# wl_phy_tx_cfg_secure register map
Vendor: Texas Instruments
Registers are 32-bit, access per field, reset 0x0 unless marked. A register's access mark holds for its fields unless they carry their own. Offsets are as the file gives them; [hi:lo] are bit positions; lines under a group give offsets from that group; {n}, {i} and the like mark numbered series.

## wl_phy_tx_cfg_secure
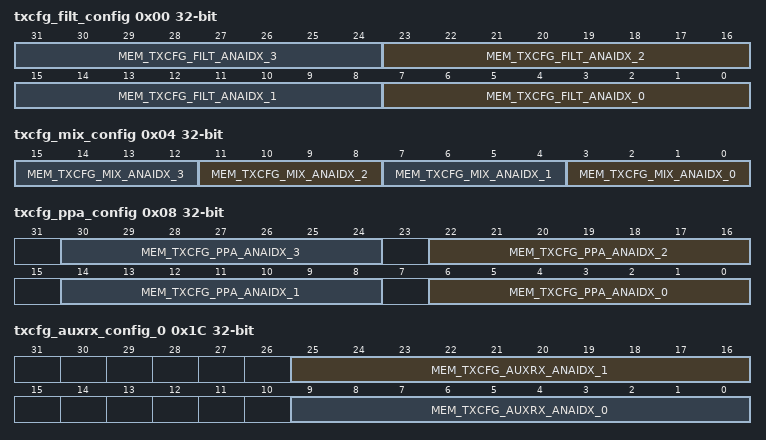
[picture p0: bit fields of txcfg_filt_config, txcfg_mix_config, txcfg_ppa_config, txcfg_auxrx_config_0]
0x00 txcfg_filt_config rw
  [8n+7:8n] MEM_TXCFG_FILT_ANAIDX_{n} (n=0..3) — Configures the specific analogue indexs (x4) Tx filter configuration.
0x04 txcfg_mix_config
  [4n+3:4n] MEM_TXCFG_MIX_ANAIDX_{n} rw (n=0..3) — Configures the specific analogue indexs (x4) Mixer configuration.
0x08 txcfg_ppa_config
  [8n+6:8n] MEM_TXCFG_PPA_ANAIDX_{n} rw (n=0..3) — Configures the specific analogue indexs(x4)PPA configuration.
{0xC+4i} txcfg_pa_config_{i} (i=0..3)
  [16:0] MEM_TXCFG_PA_ANAIDX_{i} rw — Configures the specific analogue indexs(x4)PA configuration.
0x1C txcfg_auxrx_config_0
  [25:16] MEM_TXCFG_AUXRX_ANAIDX_1 rw — Configures the specific analogue indexs(x4)Aux Rx configuration
  [9:0] MEM_TXCFG_AUXRX_ANAIDX_0 rw — Configures the specific analogue indexs(x4)Aux Rx configuration
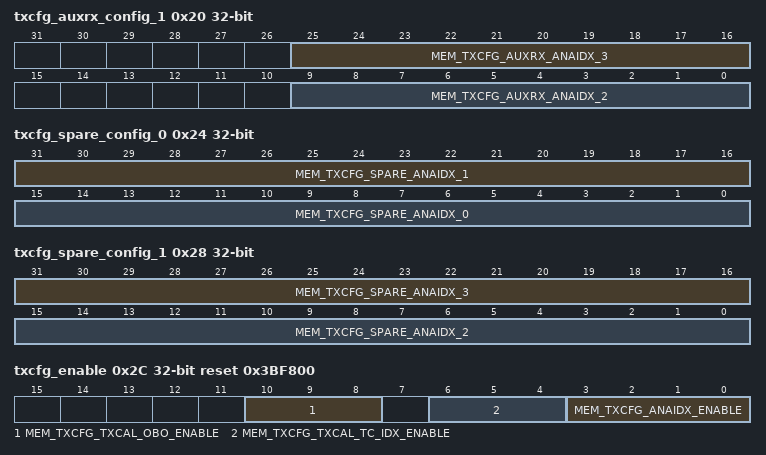
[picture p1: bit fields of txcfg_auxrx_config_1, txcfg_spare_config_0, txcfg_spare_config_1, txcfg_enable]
0x20 txcfg_auxrx_config_1
  [25:16] MEM_TXCFG_AUXRX_ANAIDX_3 rw — Configures the specific analogue indexs(x4)Aux Rx configuration
  [9:0] MEM_TXCFG_AUXRX_ANAIDX_2 rw — Configures the specific analogue indexs(x4)Aux Rx configuration
0x24 txcfg_spare_config_0 rw
  [31:16] MEM_TXCFG_SPARE_ANAIDX_1 — Spare configurations bits per analogue index(x4)
  [15:0] MEM_TXCFG_SPARE_ANAIDX_0 — Spare configurations bits per analogue index(x4)
0x28 txcfg_spare_config_1 rw
  [31:16] MEM_TXCFG_SPARE_ANAIDX_3 — Spare configurations bits per analogue index(x4)
  [15:0] MEM_TXCFG_SPARE_ANAIDX_2 — Spare configurations bits per analogue index(x4)
0x2C txcfg_enable reset 0x3BF800 (reset mask 0xFFFFF800)
  [10:8] MEM_TXCFG_TXCAL_OBO_ENABLE rw — Sets the enable regarding Tx Calibrators request to change the OBO:;MSB allows IQMM only OBO.;The next MSB allows RFNL only OBO.;LSB allows RFNL+IQMM OBO.
  [6:4] MEM_TXCFG_TXCAL_TC_IDX_ENABLE rw — Sets the enables regarding Tx Calibrators request to change the TC:;MSB allows IQMM only TC.;The next MSB allows RFNLonly TC.;LSB allows RFNL+IQMMTC.
  [3:0] MEM_TXCFG_ANAIDX_ENABLE rw — Sets the analogue index enables.MSB controls the high est powerlevel(0).LSBcontrolsthelowest(3).
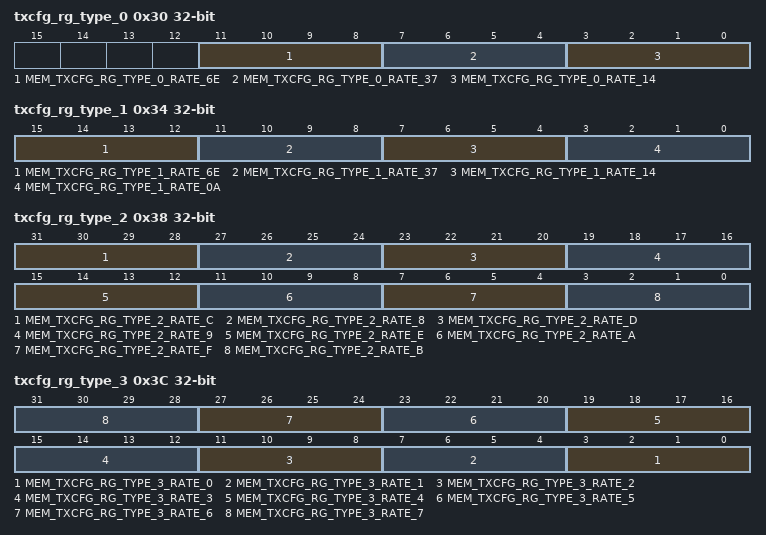
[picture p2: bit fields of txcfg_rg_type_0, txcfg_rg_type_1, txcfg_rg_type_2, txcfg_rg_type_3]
0x30 txcfg_rg_type_0
  [11:8] MEM_TXCFG_RG_TYPE_0_RATE_6E rw — Determines the transmissions rate group from a combination of the signals format and rate. See table 15-1 : Main algorithm ;Full Rate Group Logic Table for more details.
  [7:4] MEM_TXCFG_RG_TYPE_0_RATE_37 rw — Determines the transmissions rate group from a combination of the signals format and rate. See table 15-1 : Main algorithm ;Full Rate Group Logic Table for more details.
  [3:0] MEM_TXCFG_RG_TYPE_0_RATE_14 rw — Determines the transmissions rate group from a combination of the signals format and rate. See table 15-1 : Main algorithm ;Full Rate Group Logic Table for more details.
0x34 txcfg_rg_type_1
  [15:12] MEM_TXCFG_RG_TYPE_1_RATE_6E rw — Determines the transmissions rate group from a combination of the signals format and rate. See table 15-1 : Main algorithm ;Full Rate Group Logic Table for more details.
  [11:8] MEM_TXCFG_RG_TYPE_1_RATE_37 rw — Determines the transmissions rate group from a combination of the signals format and rate. See table 15-1 : Main algorithm ;Full Rate Group Logic Table for more details.
  [7:4] MEM_TXCFG_RG_TYPE_1_RATE_14 rw — Determines the transmissions rate group from a combination of the signals format and rate. See table 15-1 : Main algorithm ;Full Rate Group Logic Table for more details.
  [3:0] MEM_TXCFG_RG_TYPE_1_RATE_0A rw — Determines the transmissions rate group from a combination of the signals format and rate. See table 15-1 : Main algorithm ;Full Rate Group Logic Table for more details.
0x38 txcfg_rg_type_2 rw reset not defined
  [31:28] MEM_TXCFG_RG_TYPE_2_RATE_C — Determines the transmissions rate group from a combination of the signals format and rate. See table 15-1 : Main algorithm ;Full Rate Group Logic Table for more details.
  [27:24] MEM_TXCFG_RG_TYPE_2_RATE_8 — Determines the transmissions rate group from a combination of the signals format and rate. See table 15-1 : Main algorithm ;Full Rate Group Logic Table for more details.
  [23:20] MEM_TXCFG_RG_TYPE_2_RATE_D — Determines the transmissions rate group from a combination of the signals format and rate. See table 15-1 : Main algorithm ;Full Rate Group Logic Table for more details.
  [19:16] MEM_TXCFG_RG_TYPE_2_RATE_9 — Determines the transmissions rate group from a combination of the signals format and rate. See table 15-1 : Main algorithm ;Full Rate Group Logic Table for more details.
  [15:12] MEM_TXCFG_RG_TYPE_2_RATE_E — Determines the transmissions rate group from a combination of the signals format and rate. See table 15-1 : Main algorithm ;Full Rate Group Logic Table for more details.
  [11:8] MEM_TXCFG_RG_TYPE_2_RATE_A — Determines the transmissions rate group from a combination of the signals format and rate. See table 15-1 : Main algorithm ;Full Rate Group Logic Table for more details.
  [7:4] MEM_TXCFG_RG_TYPE_2_RATE_F — Determines the transmissions rate group from a combination of the signals format and rate. See table 15-1 : Main algorithm ;Full Rate Group Logic Table for more details.
  [3:0] MEM_TXCFG_RG_TYPE_2_RATE_B — Determines the transmissions rate group from a combination of the signals format and rate. See table 15-1 : Main algorithm ;Full Rate Group Logic Table for more details.
0x3C txcfg_rg_type_3 rw reset not defined
  [4n+3:4n] MEM_TXCFG_RG_TYPE_3_RATE_{n} (n=0..7) — Determines the transmissions rate group from a combination of the signals format and rate. See table 15-1 : Main algorithm ;Full Rate Group Logic Table for more details.
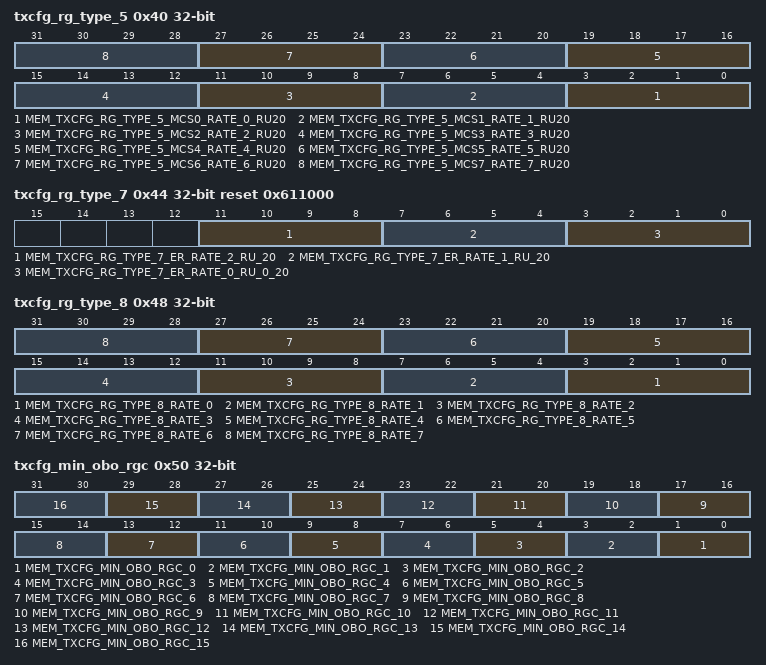
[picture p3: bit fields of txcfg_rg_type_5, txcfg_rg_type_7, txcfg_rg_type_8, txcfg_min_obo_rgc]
0x40 txcfg_rg_type_5 rw reset not defined
  [4n+3:4n] MEM_TXCFG_RG_TYPE_5_MCS{n}_RATE_{n}_RU20 (n=0..7) — Determines the transmissions rate group from a combination of the signals format and rate. See table 15-1 : Main algorithm ;Full Rate Group Logic Table for more details.
0x44 txcfg_rg_type_7 reset 0x611000 (reset mask 0xFFFFF000)
  [11:8] MEM_TXCFG_RG_TYPE_7_ER_RATE_2_RU_20 rw — Determines the transmissions rate group from a combination of the signals format and rate. See table 15-1 : Main algorithm ;Full Rate Group Logic Table for more details.
  [7:4] MEM_TXCFG_RG_TYPE_7_ER_RATE_1_RU_20 rw — Determines the transmissions rate group from a combination of the signals format and rate. See table 15-1 : Main algorithm ;Full Rate Group Logic Table for more details.
  [3:0] MEM_TXCFG_RG_TYPE_7_ER_RATE_0_RU_0_20 rw — Determines the transmissions rate group from a combination of the signals format and rate. See table 15-1 : Main algorithm ;Full Rate Group Logic Table for more details.
0x48 txcfg_rg_type_8 rw reset not defined
  [4n+3:4n] MEM_TXCFG_RG_TYPE_8_RATE_{n} (n=0..7) — Determines the transmissions rate group from a combination of the signals format and rate. See table 15-1 : Main algorithm ;Full Rate Group Logic Table for more details.
0x4C txcfg_rg_type_9 reset 0x11
  [3:0] MEM_TXCFG_RG_TYPE_9_RATE_0_RU_20 rw — Determines the transmissions rate group from a combination of the signals format and rate. See table 15-1 : Main algorithm ;Full Rate Group Logic Table for more details.
0x50 txcfg_min_obo_rgc rw
  [2n+1:2n] MEM_TXCFG_MIN_OBO_RGC_{n} (n=0..15) — Determines the Rate Group Clustering of the minimum OBO table.
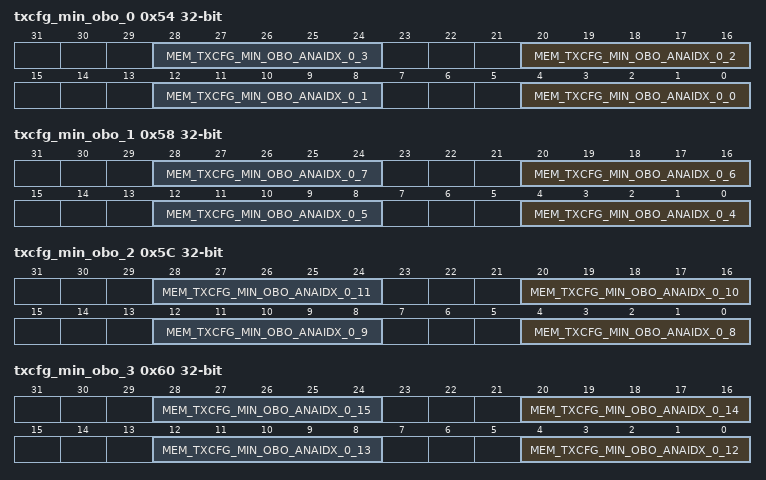
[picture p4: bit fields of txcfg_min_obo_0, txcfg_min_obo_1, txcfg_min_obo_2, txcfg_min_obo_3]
0x54 txcfg_min_obo_0
  [8n+4:8n] MEM_TXCFG_MIN_OBO_ANAIDX_0_{n} rw (n=0..3) — MinimumOBOvaluesthatensuremaskandEVMperformanceperanalogueindex(x4)andperrategroup(x16).Thereisaspecialtreatmenthere.SeeAS-12formoredetails.
0x58 txcfg_min_obo_1 reset not defined
  [8n-28:8n-32] MEM_TXCFG_MIN_OBO_ANAIDX_0_{n} rw (n=4..7) — MinimumOBOvaluesthatensuremaskandEVMperformanceperanalogueindex(x4)andperrategroup(x16).Thereisaspecialtreatmenthere.SeeAS-12formoredetails.
0x5C txcfg_min_obo_2 reset not defined
  [8n-60:8n-64] MEM_TXCFG_MIN_OBO_ANAIDX_0_{n} rw (n=8..11) — MinimumOBOvaluesthatensuremaskandEVMperformanceperanalogueindex(x4)andperrategroup(x16).Thereisaspecialtreatmenthere.SeeAS-12formoredetails.
0x60 txcfg_min_obo_3
  [8n-92:8n-96] MEM_TXCFG_MIN_OBO_ANAIDX_0_{n} rw (n=12..15) — MinimumOBOvaluesthatensuremaskandEVMperformanceperanalogueindex(x4)andperrategroup(x16).Thereisaspecialtreatmenthere.SeeAS-12formoredetails.
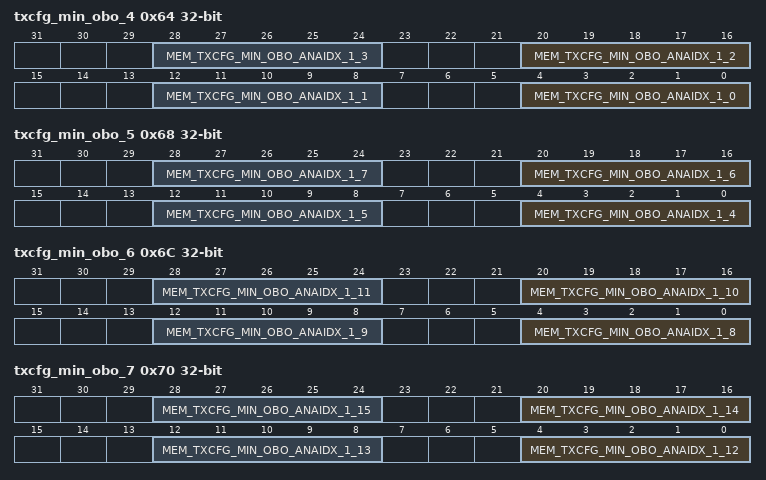
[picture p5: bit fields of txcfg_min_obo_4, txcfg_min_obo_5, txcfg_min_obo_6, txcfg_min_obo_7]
0x64 txcfg_min_obo_4
  [8n+4:8n] MEM_TXCFG_MIN_OBO_ANAIDX_1_{n} rw (n=0..3) — MinimumOBOvaluesthatensuremaskandEVMperformanceperanalogueindex(x4)andperrategroup(x16).Thereisaspecialtreatmenthere.SeeAS-12formoredetails.
0x68 txcfg_min_obo_5 reset not defined
  [8n-28:8n-32] MEM_TXCFG_MIN_OBO_ANAIDX_1_{n} rw (n=4..7) — MinimumOBOvaluesthatensuremaskandEVMperformanceperanalogueindex(x4)andperrategroup(x16).Thereisaspecialtreatmenthere.SeeAS-12formoredetails.
0x6C txcfg_min_obo_6 reset not defined
  [8n-60:8n-64] MEM_TXCFG_MIN_OBO_ANAIDX_1_{n} rw (n=8..11) — MinimumOBOvaluesthatensuremaskandEVMperformanceperanalogueindex(x4)andperrategroup(x16).Thereisaspecialtreatmenthere.SeeAS-12formoredetails.
0x70 txcfg_min_obo_7 reset not defined
  [8n-92:8n-96] MEM_TXCFG_MIN_OBO_ANAIDX_1_{n} rw (n=12..15) — MinimumOBOvaluesthatensuremaskandEVMperformanceperanalogueindex(x4)andperrategroup(x16).Thereisaspecialtreatmenthere.SeeAS-12formoredetails.
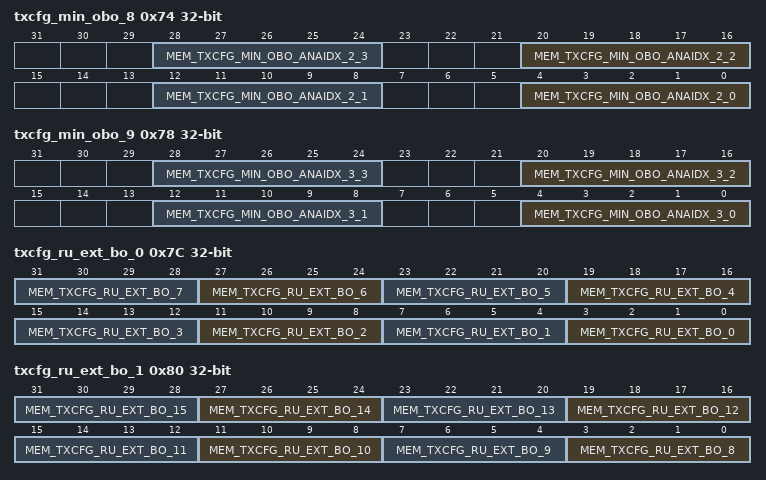
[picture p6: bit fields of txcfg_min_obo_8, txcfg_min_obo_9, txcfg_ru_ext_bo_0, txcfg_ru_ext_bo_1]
0x74 txcfg_min_obo_8
  [8n+4:8n] MEM_TXCFG_MIN_OBO_ANAIDX_2_{n} rw (n=0..3) — MinimumOBOvaluesthatensuremaskandEVMperformanceperanalogueindex(x4)andperrategroup(x16).Thereisaspecialtreatmenthere.SeeAS-12formoredetails.
0x78 txcfg_min_obo_9
  [8n+4:8n] MEM_TXCFG_MIN_OBO_ANAIDX_3_{n} rw (n=0..3) — MinimumOBOvaluesthatensuremaskandEVMperformanceperanalogueindex(x4)andperrategroup(x16).Thereisaspecialtreatmenthere.SeeAS-12formoredetails.
0x7C txcfg_ru_ext_bo_0 rw
  [4n+3:4n] MEM_TXCFG_RU_EXT_BO_{n} (n=0..7) — Extra11axOBOcompensationindBperRUposition(x16).HE-TBandHE-ERupperarerelevanthere.ValueisindB.
0x80 txcfg_ru_ext_bo_1 rw
  [4n-29:4n-32] MEM_TXCFG_RU_EXT_BO_{n} (n=8..15) — Extra11axOBOcompensationindBperRUposition(x16).HE-TBandHE-ERupperarerelevanthere.ValueisindB.
0x84 txcfg_max_tb_mcs7_power
  [8:0] MEM_TXCFG_MAX_TB_MCS7_POWER rw — ShowsthemaxpowerforHEMCS7transmission.Usedforchoosingbetweenhighorlowpowertrans
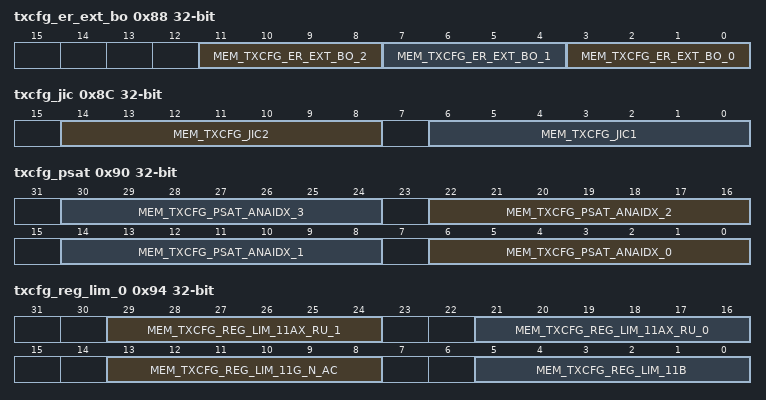
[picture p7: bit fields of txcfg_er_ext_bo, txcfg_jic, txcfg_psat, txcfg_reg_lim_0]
0x88 txcfg_er_ext_bo
  [11:8] MEM_TXCFG_ER_EXT_BO_2 rw — Extra11axHE-EROBOcompensationindBperRate(x3-MCS0-2).ValueisindB.
  [7:4] MEM_TXCFG_ER_EXT_BO_1 rw — Extra11axHE-EROBOcompensationindBperRate(x3-MCS0-2).ValueisindB.
  [3:0] MEM_TXCFG_ER_EXT_BO_0 rw — Extra11axHE-EROBOcompensationindBperRate(x3-MCS0-2).ValueisindB.
0x8C txcfg_jic
  [14:8] MEM_TXCFG_JIC2 rw — JustInCaseregister#2isaregisterthatwillbeusedincasethereisaspecialoccasionandweneedtoinsertacertainvaluewedidntthinkof.ItislocatednexttotheBsectionofthealgorithmcomparator.
  [6:0] MEM_TXCFG_JIC1 rw — JustInCaseregister#1isaregisterthatwillbeusedincasethereisaspecialoccasionandweneedtoinsertacertainvaluewedidntthinkof.ItislocatednexttotheAsectionofthealgorithmcomparator.
0x90 txcfg_psat
  [8n+6:8n] MEM_TXCFG_PSAT_ANAIDX_{n} rw (n=0..3) — PsatvaluesindBmforeachanaloguesettingindex(x4).ValueisindBm.
0x94 txcfg_reg_lim_0
  [29:24] MEM_TXCFG_REG_LIM_11AX_RU_1 rw — Regulatorylimitsperregion dependingontherateandtheRUpositionofourtransmission.(x11forax x1forbandx1fora/g/n/ac.SeeTable7-6:Mainalgorithm;RegulationTableformoredetails.ValueisindBm.
  [21:16] MEM_TXCFG_REG_LIM_11AX_RU_0 rw — Regulatorylimitsperregion dependingontherateandtheRUpositionofourtransmission.(x11forax x1forbandx1fora/g/n/ac.SeeTable7-6:Mainalgorithm;RegulationTableformoredetails.ValueisindBm.
  [13:8] MEM_TXCFG_REG_LIM_11G_N_AC rw — Regulatorylimitsperregion dependingontherateandtheRUpositionofourtransmission.(x11forax x1forbandx1fora/g/n/ac.SeeTable7-6:Mainalgorithm;RegulationTableformoredetails.ValueisindBm.
  [5:0] MEM_TXCFG_REG_LIM_11B rw — Regulatorylimitsperregion dependingontherateandtheRUpositionofourtransmission.(x11forax x1forbandx1fora/g/n/ac.SeeTable7-6:Mainalgorithm;RegulationTableformoredetails.ValueisindBm.
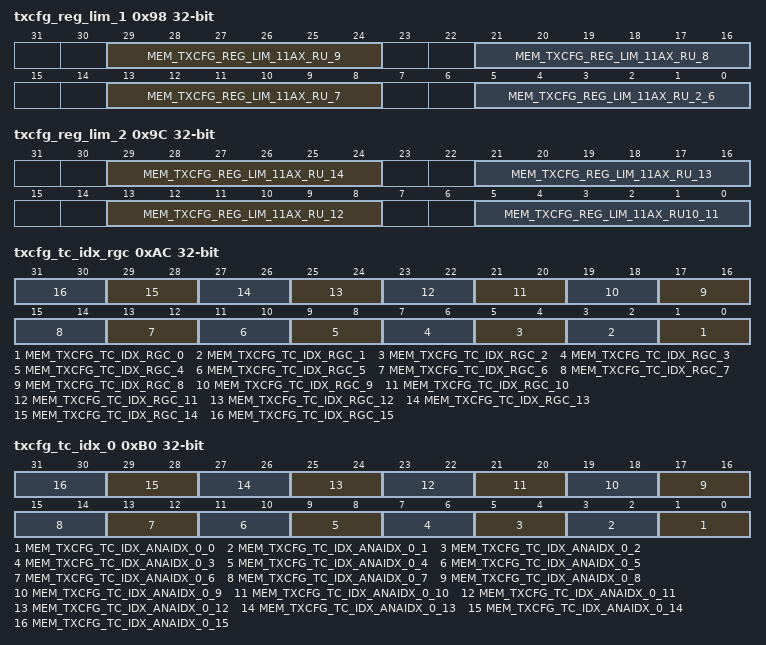
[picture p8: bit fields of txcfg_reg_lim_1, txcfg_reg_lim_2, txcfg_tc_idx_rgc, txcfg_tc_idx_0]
0x98 txcfg_reg_lim_1
  [29:24] MEM_TXCFG_REG_LIM_11AX_RU_9 rw — Regulatorylimitsperregion dependingontherateandtheRUpositionofourtransmission.(x11forax x1forbandx1fora/g/n/ac.SeeTable7-6:Mainalgorithm;RegulationTableformoredetails.ValueisindBm.
  [21:16] MEM_TXCFG_REG_LIM_11AX_RU_8 rw — Regulatorylimitsperregion dependingontherateandtheRUpositionofourtransmission.(x11forax x1forbandx1fora/g/n/ac.SeeTable7-6:Mainalgorithm;RegulationTableformoredetails.ValueisindBm.
  [13:8] MEM_TXCFG_REG_LIM_11AX_RU_7 rw — Regulatorylimitsperregion dependingontherateandtheRUpositionofourtransmission.(x11forax x1forbandx1fora/g/n/ac.SeeTable7-6:Mainalgorithm;RegulationTableformoredetails.ValueisindBm.
  [5:0] MEM_TXCFG_REG_LIM_11AX_RU_2_6 rw — Regulatorylimitsperregion dependingontherateandtheRUpositionofourtransmission.(x11forax x1forbandx1fora/g/n/ac.SeeTable7-6:Mainalgorithm;RegulationTableformoredetails.ValueisindBm.
0x9C txcfg_reg_lim_2
  [29:24] MEM_TXCFG_REG_LIM_11AX_RU_14 rw — Regulatorylimitsperregion dependingontherateandtheRUpositionofourtransmission.(x11forax x1forbandx1fora/g/n/ac.SeeTable7-6:Mainalgorithm;RegulationTableformoredetails.ValueisindBm.
  [21:16] MEM_TXCFG_REG_LIM_11AX_RU_13 rw — Regulatorylimitsperregion dependingontherateandtheRUpositionofourtransmission.(x11forax x1forbandx1fora/g/n/ac.SeeTable7-6:Mainalgorithm;RegulationTableformoredetails.ValueisindBm.
  [13:8] MEM_TXCFG_REG_LIM_11AX_RU_12 rw — Regulatorylimitsperregion dependingontherateandtheRUpositionofourtransmission.(x11forax x1forbandx1fora/g/n/ac.SeeTable7-6:Mainalgorithm;RegulationTableformoredetails.ValueisindBm.
  [5:0] MEM_TXCFG_REG_LIM_11AX_RU10_11 rw — Regulatorylimitsperregion dependingontherateandtheRUpositionofourtransmission.(x11forax x1forbandx1fora/g/n/ac.SeeTable7-6:Mainalgorithm;RegulationTableformoredetails.ValueisindBm.
0xA0 txcfg_reg_lim_3
  [5:0] MEM_TXCFG_REG_LIM_11AX_RU_15 rw — Regulatorylimitsperregion dependingontherateandtheRUpositionofourtransmission.(x11forax x1forbandx1fora/g/n/ac.SeeTable7-6:Mainalgorithm;RegulationTableformoredetails.ValueisindBm.
0xA4 txcfg_thermal_protect reset 0x3FF
  [4:0] MEM_TXCFG_THERMAL_PROTECT rw — Thisregisterholdsthemaximumpowervalueavailableinourantenna.Thiscomesasathermaleventprotection.
0xA8 txcfg_insert_loss
  [5:0] MEM_TXCFG_INSERT_LOSS rw — ThevalueinthisregisterrepresentstheinsertionlossofthepathbetweentheSOCtotheAntenna.ValueisindB.
0xAC txcfg_tc_idx_rgc rw
  [2n+1:2n] MEM_TXCFG_TC_IDX_RGC_{n} (n=0..15) — DeterminestheRateGroupClusteringoftheTCIdxtable.
0xB0 txcfg_tc_idx_0 rw reset not defined
  [2n+1:2n] MEM_TXCFG_TC_IDX_ANAIDX_0_{n} (n=0..15) — Determinethetargetcurveindicesdependingonthetransmissionsrategroup(x16)andtheanalogueindex(x4).Thereisaspecialtreatmenthere.SeeAS-13formoredetails.
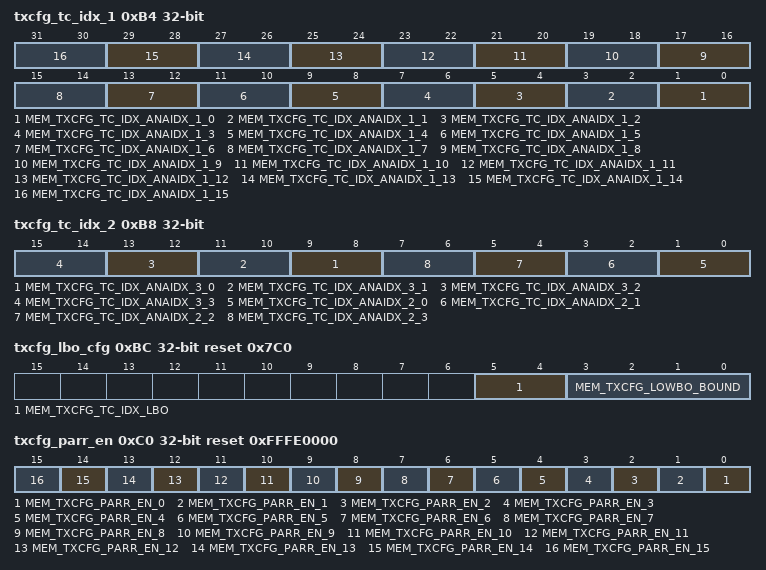
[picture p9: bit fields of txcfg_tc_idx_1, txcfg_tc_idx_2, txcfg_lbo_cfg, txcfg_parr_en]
0xB4 txcfg_tc_idx_1 rw reset not defined
  [2n+1:2n] MEM_TXCFG_TC_IDX_ANAIDX_1_{n} (n=0..15) — Determinethetargetcurveindicesdependingonthetransmissionsrategroup(x16)andtheanalogueindex(x4).Thereisaspecialtreatmenthere.SeeAS-13formoredetails.
0xB8 txcfg_tc_idx_2
  [2n+9:2n+8] MEM_TXCFG_TC_IDX_ANAIDX_3_{n} rw (n=0..3) — Determinethetargetcurveindicesdependingonthetransmissionsrategroup(x16)andtheanalogueindex(x4).Thereisaspecialtreatmenthere.SeeAS-13formoredetails.
  [2n+1:2n] MEM_TXCFG_TC_IDX_ANAIDX_2_{n} rw (n=0..3) — Determinethetargetcurveindicesdependingonthetransmissionsrategroup(x16)andtheanalogueindex(x4).Thereisaspecialtreatmenthere.SeeAS-13formoredetails.
0xBC txcfg_lbo_cfg reset 0x7C0 (reset mask 0xFFFFFFC0)
  [5:4] MEM_TXCFG_TC_IDX_LBO rw — HoldstheTCIdxforLowBOmodestargetcurve.
  [3:0] MEM_TXCFG_LOWBO_BOUND rw — IfthecalculatedBOequalsorbelowthevalueinthisregister thenweareinlowBOmode.
0xC0 txcfg_parr_en reset 0xFFFE0000 (reset mask 0xFFFF0000)
  [n] MEM_TXCFG_PARR_EN_{n} rw (n=0..15) — EnablesthePARRmoduledependingonthetransmissionsrategroup(x16).
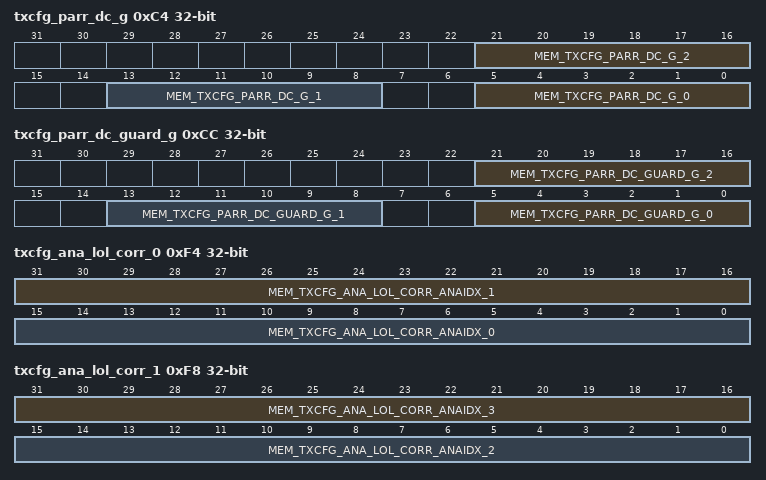
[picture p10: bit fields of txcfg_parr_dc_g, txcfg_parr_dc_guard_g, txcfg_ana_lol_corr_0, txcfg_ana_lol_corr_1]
0xC4 txcfg_parr_dc_g
  [21:16] MEM_TXCFG_PARR_DC_G_2 rw — PARRmodules3optionsofDCgain.
  [13:8] MEM_TXCFG_PARR_DC_G_1 rw — PARRmodules3optionsofDCgain.
  [5:0] MEM_TXCFG_PARR_DC_G_0 rw — PARRmodules3optionsofDCgain.
0xC8 txcfg_parr_dc_w
  [7:0] MEM_TXCFG_PARR_DC_W rw — PARRmodulesDCmaskclip.
0xCC txcfg_parr_dc_guard_g
  [21:16] MEM_TXCFG_PARR_DC_GUARD_G_2 rw — PARRmodules3optionsofDCguardgain.
  [13:8] MEM_TXCFG_PARR_DC_GUARD_G_1 rw — PARRmodules3optionsofDCguardgain.
  [5:0] MEM_TXCFG_PARR_DC_GUARD_G_0 rw — PARRmodules3optionsofDCguardgain.
0xD0 txcfg_parr_dc_guard_w
  [7:0] MEM_TXCFG_PARR_DC_GUARD_W rw — PARRmodulesDCGuardmaskclip.
{0xD4+4i} txcfg_iqmm_corr_{i} (i=0..3)
  [17:0] MEM_TXCFG_IQMM_CORR_ANAIDX_{i} rw — PandGcorrectionsforIQMMperAnalogueIndex(x4).
{0xE4+4i} txcfg_lol_corr_{i} (i=0..3)
  [23:0] MEM_TXCFG_LOL_CORR_ANAIDX_{i} rw — IandQdigitalcorrectionsforLOLperAnalogueIndex(x4).
0xF4 txcfg_ana_lol_corr_0 rw
  [31:16] MEM_TXCFG_ANA_LOL_CORR_ANAIDX_1 — IandQanaloguecorrectionsforLOLperAnalogueIndex(x4).
  [15:0] MEM_TXCFG_ANA_LOL_CORR_ANAIDX_0 — IandQanaloguecorrectionsforLOLperAnalogueIndex(x4).
0xF8 txcfg_ana_lol_corr_1 rw
  [31:16] MEM_TXCFG_ANA_LOL_CORR_ANAIDX_3 — IandQanaloguecorrectionsforLOLperAnalogueIndex(x4).
  [15:0] MEM_TXCFG_ANA_LOL_CORR_ANAIDX_2 — IandQanaloguecorrectionsforLOLperAnalogueIndex(x4).
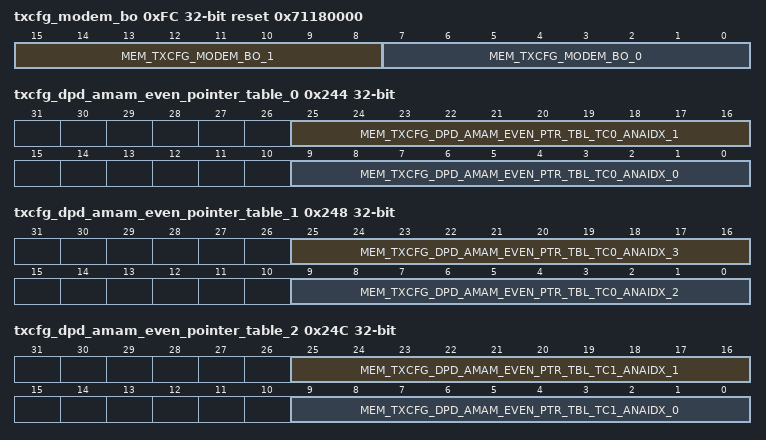
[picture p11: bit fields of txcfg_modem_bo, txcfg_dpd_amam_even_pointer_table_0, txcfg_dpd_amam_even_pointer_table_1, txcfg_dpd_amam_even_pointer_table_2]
0xFC txcfg_modem_bo reset 0x71180000 (reset mask 0xFFFF0000)
  [15:8] MEM_TXCFG_MODEM_BO_1 rw — TheModemsBOattheFFTsoutput.Thedifferenceisbetween11bandnon-11b.ValueisindB.
  [7:0] MEM_TXCFG_MODEM_BO_0 rw — TheModemsBOattheFFTsoutput.Thedifferenceisbetween11bandnon-11b.ValueisindB.
0x100 txcfg_post_dpd_gain
  [5:0] MEM_TXCFG_POST_DPD_GAIN_WROPT rw — ThisvalueisaddedtotheDPDBackoffvaluecalculatedbytheTxConfigtogettheBackoffAndPostGainCoarse/Finevalues.
0x104 txcfg_txcal_tc_idx_iqmm
  [1:0] MEM_TXCFG_TXCAL_TC_IDX_IQMM rw — Target curve index override incase we use the Tx calibrator only the IQMM calibration.
0x108 txcfg_txcal_tc_idx_rfnl
  [1:0] MEM_TXCFG_TXCAL_TC_IDX_RFNL rw — Target curve index override incase we use the Tx calibrator only the RFNL calibration.
0x10C txcfg_txcal_tc_idx_both
  [1:0] MEM_TXCFG_TXCAL_TC_IDX_BOTH rw — Target curve index override incase we use the Tx calibrator both IQMM and RFNL calibrations.
0x110 txcfg_txcal_obo_iqmm
  [4:0] MEM_TXCFG_TXCAL_OBO_IQMM rw — OBOoverride incase we use the Tx calibrator only the IQMMc alibration.Value is in dB.
0x114 txcfg_txcal_obo_rfnl
  [4:0] MEM_TXCFG_TXCAL_OBO_RFNL rw — OBOoverride incase we use the Tx calibrator only the RFNL calibration.Value is in dB.
0x118 txcfg_txcal_obo_both
  [4:0] MEM_TXCFG_TXCAL_OBO_BOTH rw — OBOoverride incase we use the Tx calibrator both IQMM and RFNL calibrations.Value is in dB.
0x11C txcfg_obo2ibo_delay reset 0x66
  [3:0] MEM_TXCFG_OBO2IBO_DELAY rw — SetsthedelayoftheOBO2IBOmodule.ItstartswhenTxHDRisinitiated.Valueisclockcycles.UsedforgivinganoptionfortheTxCalibratortointerferewithourchoices.
0x120 txcfg_filt_config_chosen ro
  [7:0] TXCFG_FILT_CONFIG_CHOSEN — Status RO register that indicates the chosen Tx filter configurations.
0x124 txcfg_mix_config_chosen ro
  [3:0] TXCFG_MIX_CONFIG_CHOSEN — Status RO register that indicates the chosen mixer configurations.
0x128 txcfg_ppa_config_chosen ro
  [6:0] TXCFG_PPA_CONFIG_CHOSEN — Status RO register that indicates the chosen PPA configurations.
0x12C txcfg_pa_config_chosen ro
  [16:0] TXCFG_PA_CONFIG_CHOSEN — Status RO register that indicates the chosen PA configurations.
0x130 txcfg_auxrx_config_chosen ro
  [9:0] TXCFG_AUXRX_CONFIG_CHOSEN — Status RO register that indicates the chosen AuxRx configurations bits.
0x134 txcfg_spare_config_chosen ro
  [15:0] TXCFG_SPARE_CONFIG_CHOSEN — Status RO register that indicates the chosen Spare configruations bits.
0x138 txcfg_min_obo_chosen ro
  [4:0] TXCFG_MIN_OBO_CHOSEN — Status RO register that indicates the chosen minimal OBO.Value is in dB.
0x13C txcfg_min_obo_rgc_chosen ro
  [1:0] TXCFG_MIN_OBO_RGC_CHOSEN — Status RO register that indicates the chosen minimum OBORGC.
0x140 txcfg_rg_chosen ro
  [3:0] TXCFG_RG_CHOSEN — Status RO register that indicates the chosen RG.
0x144 txcfg_anaidx_chosen ro
  [1:0] TXCFG_ANAIDX_CHOSEN — Status RO register that indicates the chosen Ana Idx.
0x148 txcfg_ru_ext_bo_chosen ro
  [3:0] TXCFG_RU_EXT_BO_CHOSEN — Status RO register that indicates the chosen RUExtraBO.Value is in dB.
0x14C txcfg_er_ext_bo_chosen ro
  [3:0] TXCFG_ER_EXT_BO_CHOSEN — Status RO register that indicates the chosen ERExtraBO.Value is in dB.
0x150 txcfg_psat_chosen ro
  [6:0] TXCFG_PSAT_CHOSEN — Status RO register that indicates the chosen Psatvalue.Value is in dBm.
0x154 txcfg_reg_lim_chosen ro
  [5:0] TXCFG_REG_LIM_CHOSEN — Status RO register that indicates the chosen Regulation limit value.Value is in dBm.
0x158 txcfg_low_bo_mode ro
  [0] TXCFG_LOW_BO_MODE — TellsusifweareinLowBOmode.
0x15C txcfg_tb_power_less_mcs7 ro
  [0] TXCFG_TB_POWER_LESS_MCS7 — TellsusifwetransmitTBandthecalculatedoutputpowerislowerorequalstothemaxMCS7transmissionpower.
0x160 txcfg_obo_calc ro
  [7:0] TXCFG_OBO_CALC — Status RO register that indicates the calculatedOBO.Value is in dB.
0x164 txcfg_obo_chosen ro
  [7:0] TXCFG_OBO_CHOSEN — Status RO register that indicates the chosenOBO.Value is in dB.
0x168 txcfg_txcfgobo_ready ro
  [0] TXCFG_OBO_CALC_READY — StatusROregisterthatindicatesthatthewehavefoundthedesiredAnaIdxanditscorrespondingOBO.
0x16C txcfg_obo_ready ro
  [0] TXCFG_OBO_READY — StatusROregisterthatindicatesthattheOBOisnowfinal(afteritwaschanged/notchangedbytheTxCalibrator).
0x170 txcfg_tc_idx_chosen ro
  [1:0] TXCFG_TC_IDX_CHOSEN — Status RO register that indicates the chosen TC.
0x174 txcfg_tc_idx_rgc_chosen ro
  [1:0] TXCFG_TC_IDX_RGC_CHOSEN — Status RO register that indicates the chosen TC.dxRGC.
0x178 txcfg_parr_en_chosen ro
  [0] TXCFG_PARR_EN_CHOSEN — Status RO register that indicates the chosen PARR enable signal.
0x17C txcfg_parr_dc_g_chosen ro
  [5:0] TXCFG_PARR_DC_G_CHOSEN — ChosenPAPRmodulesDCgainvalue.
0x180 txcfg_parr_dc_guard_g_chosen ro
  [5:0] TXCFG_PARR_DC_GUARD_G_CHOSEN — ChosenPAPRmodulesDCGuardgainvalue.
0x184 txcfg_iqmm_corr_chosen ro
  [17:0] TXCFG_IQMM_CORR_CHOSEN — StatusROregisterthatindicatesthechosenTxIQMMcorrection.
0x188 txcfg_lol_corr_chosen ro
  [23:0] TXCFG_LOL_CORR_CHOSEN — Status RO register that indicates the chosen TxLOL correction.
0x18C txcfg_ana_lol_corr_chosen ro
  [15:0] TXCFG_ANA_LOL_CORR_CHOSEN — StatusROregisterthatindicatesIandQanaloguecorrectionsforLOLperAnalogueIndex(x4).
0x190 txcfg_shaping_mirror_chosen ro
  [0] TXCFG_SHP_MIR_CHOSEN — Status RO register that indicates the chosen Shaping Mirror option.
0x194 txcfg_ibo ro
  [8:0] TXCFG_IBO — Status RO register that indicates the calculated IBO value.
0x198 txcfg_modem_bo_chosen ro
  [7:0] TXCFG_MODEM_BO_CHOSEN — Status RO register that indicates the chosen modem OBO.Value is in dB.
0x19C txcfg_fine_gain_calc ro
  [8:0] TXCFG_FINE_GAIN_CALC — StatusROregisterthatindicatesthecalculatedfinegain.
0x1A0 txcfg_coarse_gain_calc ro
  [1:0] TXCFG_COARSE_GAIN_CALC — Status RO register that indicates the calculated coarse gain.
0x1A4 txcfg_post_fine_gain_calc ro
  [8:0] TXCFG_POST_FINE_GAIN_CALC — StatusROregisterthatindicatesthecalculatedpostfinegain.
0x1A8 txcfg_post_coarse_gain_calc ro
  [1:0] TXCFG_POST_COARSE_GAIN_CALC — Status RO register that indicates the calculated post coarse gain.
0x1AC txcfg_fine_gain_chosen ro
  [8:0] TXCFG_FINE_GAIN_CHOSEN — Status RO register that indicates the chosen fine gain.
0x1B0 txcfg_coarse_gain_chosen ro
  [1:0] TXCFG_COARSE_GAIN_CHOSEN — Status RO register that indicates the chosen coarse gain.
0x1B4 txcfg_post_fine_gain_chosen ro
  [8:0] TXCFG_POST_FINE_GAIN_CHOSEN — Status RO register that indicates the chosen post fine gain.
0x1B8 txcfg_post_coarse_gain_chosen ro
  [1:0] TXCFG_POST_COARSE_GAIN_CHOSEN — StatusROregisterthatindicatesthechosenpostcoarsegain.
0x1BC txcfg_force_filt_config
  [0] MEM_TXCFG_FORCE_FILT_CONFIG rw — ForcestheTxConfigmoduletouseaspecificTxfilterconfigurationfromadesignatedregister:TXCFG_FILT_CONFIG_OVD.
0x1C0 txcfg_filt_config_ovd
  [7:0] MEM_TXCFG_FILT_CONFIG_OVD rw — OverridestheTxfilterconfigurationsthatwereselectedbytheTxConfigModulewithapre-determinedvalue.
0x1C4 txcfg_force_mix_config
  [0] MEM_TXCFG_FORCE_MIX_CONFIG rw — ForcestheTxConfigmoduletouseaspecificmixerconfigurationfromadesignatedregister:TXCFG_MIX_CONFIG_OVD.
0x1C8 txcfg_mix_config_ovd
  [3:0] MEM_TXCFG_MIX_CONFIG_OVD rw — OverridesMixer1configurationsthatwereselectedbytheTxConfigModulewithapre-determinedvalue.
0x1CC txcfg_force_ppa_config
  [0] MEM_TXCFG_FORCE_PPA_CONFIG rw — ForcestheTxConfigmoduletouseaspecificPPAconfigurationfromadesignatedregister:TXCFG_PPA_CONFIG_OVD.
0x1D0 txcfg_ppa_config_ovd
  [6:0] MEM_TXCFG_PPA_CONFIG_OVD rw — OverridesthePPAconfigurationsthatwereselectedbytheTxConfigModulewithapre-determinedvalue.
0x1D4 txcfg_force_pa_config
  [0] MEM_TXCFG_FORCE_PA_CONFIG rw — ForcestheTxConfigmoduletouseaspecificPAconfigurationfromadesignatedregister:TXCFG_PA_CONFIG_OVD.
0x1D8 txcfg_pa_config_ovd
  [16:0] MEM_TXCFG_PA_CONFIG_OVD rw — OverridesthePAconfigurationsthatwereselectedbytheTxConfigModulewithapre-determinedvalue.
0x1DC txcfg_force_auxrx_config
  [0] MEM_TXCFG_FORCE_AUXRX_CONFIG rw — ForcestheTxConfigmoduletouseaspecificAuxRxbitsconfigurationfromadesignatedregister:TXCFG_AUXRX_CONFIG_OVD
0x1E0 txcfg_auxrx_config_ovd
  [9:0] MEM_TXCFG_AUXRX_CONFIG_OVD rw — OverridestheAuxRxconfigurationsthatwereselectedbytheTxConfigModulewithapre-determinedvalue.
0x1E4 txcfg_force_spare
  [0] MEM_TXCFG_FORCE_SPARE rw — ForcestheTxConfigmoduletouseaspecificSparebitsconfigurationfromadesignatedregister:TXCFG_SPARE_OVD
0x1E8 txcfg_spare_ovd
  [15:0] MEM_TXCFG_SPARE_OVD rw — OverridestheSparebitsthatwereselectedbytheTxConfigModulewithapre-determinedvalue.
0x1EC txcfg_force_anaidx
  [0] MEM_TXCFG_FORCE_ANAIDX rw — ForcestheTxConfigmoduletouseaspecificAnalogueIndexfromadesignatedregister:TXCFG_ANAIDX_OVD.
0x1F0 txcfg_anaidx_ovd
  [1:0] MEM_TXCFG_ANAIDX_OVD rw — OverridestheAnalogueindexthatwasselectedbytheTxConfigModulewithapre-determinedvalue.TxConfigusesthisindexforconfiguringitsoutputsandnotattheinnerloop(OBOisnotaffected)!
0x1F4 txcfg_force_rg
  [0] MEM_TXCFG_FORCE_RG rw — ForcestheTxConfigmoduletouseaspecificRateGroupfromadesignatedregister:TXCFG_RG_OVD.
0x1F8 txcfg_rg_ovd
  [3:0] MEM_TXCFG_RG_OVD rw — OverridestheRategroupvaluethatwasselectedbytheTxConfigModulewithapre-determinedvalue.
0x1FC txcfg_force_obo
  [0] MEM_TXCFG_FORCE_OBO rw — ForcestheTxConfigmoduletousetheOBOsettingsfromadesignatedregister:TXCFG_OBO_OVD.
0x200 txcfg_obo_ovd
  [7:0] MEM_TXCFG_OBO_OVD rw — OverridestheOBOvaluethatwasselectedbytheTxConfigModulewithapre-determinedvalue.ValueisindB.
0x204 txcfg_force_tc_idx
  [0] MEM_TXCFG_FORCE_TC_IDX rw — ForcestheTxConfigmoduletousetheTCindexfromadesignatedregister:TXCFG_TC_IDX_OVD.
0x208 txcfg_tc_idx_ovd
  [1:0] MEM_TXCFG_TC_IDX_OVD rw — OverridestheTargetcurveindexthatwasselectedbytheTxConfigModulewithapre-determinedvalue.
0x20C txcfg_force_parr_en
  [0] MEM_TXCFG_FORCE_PARR_EN rw — ForcestheTxConfigmoduletousethePARR-Enableoptionfromadesignatedregister:TXCFG_PARR_EN_OVD.
0x210 txcfg_parr_en_ovd
  [0] MEM_TXCFG_PARR_EN_OVD rw — OverridesthePARRenablevaluethatwasselectedbytheTxConfigModulewithapre-determinedvalue.
0x214 txcfg_force_parr_dc_g
  [0] MEM_TXCFG_FORCE_PARR_DC_G rw — ForcestheTxConfigmoduletouseaspecificDCgainvalue.
0x218 txcfg_parr_dc_g_ovd
  [5:0] MEM_TXCFG_PARR_DC_G_OVD rw — OverridesthePARRDCgainvalueselectedbytheTxConfigModule.
0x21C txcfg_force_parr_dc_guard_g
  [0] MEM_TXCFG_FORCE_PARR_DC_GUARD_G rw — ForcestheTxConfigmoduletouseaspecificDCGuardgainvalue.
0x220 txcfg_parr_dc_guard_g_ovd
  [5:0] MEM_TXCFG_PARR_DC_GUARD_G_OVD rw — OverridesthePARRDCGuardgainvalueselectedbytheTxConfigModule.
0x224 txcfg_force_iqmm_corr
  [0] MEM_TXCFG_FORCE_IQMM_CORR rw — ForcestheTxConfigmoduletouseaspecificIQMMfixfromadesignatedregister:TXCFG_IQMM_CORR_OVD.
0x228 txcfg_iqmm_corr_ovd
  [17:0] MEM_TXCFG_IQMM_CORR_OVD rw — OverridestheIQMMfixthatwasselectedbytheTxConfigModulewithapre-determinedvalue.
0x22C txcfg_force_lol_corr
  [0] MEM_TXCFG_FORCE_LOL_CORR rw — ForcestheTxConfigmoduletouseaspecificLOLfixfromadesignatedregister:TXCFG_LOL_CORR_OVD.
0x230 txcfg_lol_corr_ovd
  [23:0] MEM_TXCFG_LOL_CORR_OVD rw — OverridestheLOLfixthatwasselectedbytheTxConfigModulewithapre-determinedvalue.
0x234 txcfg_force_ana_lol_corr
  [0] MEM_TXCFG_FORCE_ANA_LOL_CORR rw — ForcestheTxConfigmoduletouseaspecificAnalogueLOLfixfromadesignatedregister:TXCFG_ANA_LOL_CORR_OVD.
0x238 txcfg_ana_lol_corr_ovd
  [15:0] MEM_TXCFG_ANA_LOL_CORR_OVD rw — OverridestheanalogueLOLfixthatwasselectedbytheTxConfigModulewithapre-determinedvalue.
0x23C txcfg_force_shaping_mirror
  [0] MEM_TXCFG_FORCE_SHP_MIR rw — ForcestheTxConfigmoduletooutputaspecificshapingmirroroptionfromadesignatedregister:TXCFG_SHAPING_MIRROR_OVD.
0x240 txcfg_shaping_mirror_ovd
  [0] MEM_TXCFG_SHP_MIR_OVD rw — OverridestheshapingmirroroptionselectedbytheTxConfigModulewithapre-determinedvalue.
0x244 txcfg_dpd_amam_even_pointer_table_0
  [25:16] MEM_TXCFG_DPD_AMAM_EVEN_PTR_TBL_TC0_ANAIDX_1 rw — StoresthepointerstothefirstaddressesoftheDPDsAMAMevencoefficienttablesdependingontheanalogueindex(x4)andtheTCindex(x3).
  [9:0] MEM_TXCFG_DPD_AMAM_EVEN_PTR_TBL_TC0_ANAIDX_0 rw — StoresthepointerstothefirstaddressesoftheDPDsAMAMevencoefficienttablesdependingontheanalogueindex(x4)andtheTCindex(x3).
0x248 txcfg_dpd_amam_even_pointer_table_1
  [25:16] MEM_TXCFG_DPD_AMAM_EVEN_PTR_TBL_TC0_ANAIDX_3 rw — StoresthepointerstothefirstaddressesoftheDPDsAMAMevencoefficienttablesdependingontheanalogueindex(x4)andtheTCindex(x3).
  [9:0] MEM_TXCFG_DPD_AMAM_EVEN_PTR_TBL_TC0_ANAIDX_2 rw — StoresthepointerstothefirstaddressesoftheDPDsAMAMevencoefficienttablesdependingontheanalogueindex(x4)andtheTCindex(x3).
0x24C txcfg_dpd_amam_even_pointer_table_2
  [25:16] MEM_TXCFG_DPD_AMAM_EVEN_PTR_TBL_TC1_ANAIDX_1 rw — StoresthepointerstothefirstaddressesoftheDPDsAMAMevencoefficienttablesdependingontheanalogueindex(x4)andtheTCindex(x3).
  [9:0] MEM_TXCFG_DPD_AMAM_EVEN_PTR_TBL_TC1_ANAIDX_0 rw — StoresthepointerstothefirstaddressesoftheDPDsAMAMevencoefficienttablesdependingontheanalogueindex(x4)andtheTCindex(x3).
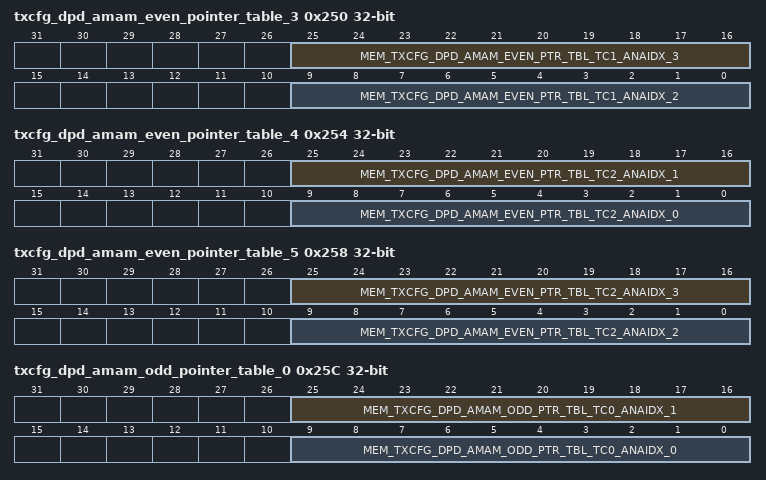
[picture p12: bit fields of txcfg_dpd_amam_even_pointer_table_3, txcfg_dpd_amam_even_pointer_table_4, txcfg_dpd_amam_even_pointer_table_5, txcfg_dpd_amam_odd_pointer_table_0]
0x250 txcfg_dpd_amam_even_pointer_table_3
  [25:16] MEM_TXCFG_DPD_AMAM_EVEN_PTR_TBL_TC1_ANAIDX_3 rw — StoresthepointerstothefirstaddressesoftheDPDsAMAMevencoefficienttablesdependingontheanalogueindex(x4)andtheTCindex(x3).
  [9:0] MEM_TXCFG_DPD_AMAM_EVEN_PTR_TBL_TC1_ANAIDX_2 rw — StoresthepointerstothefirstaddressesoftheDPDsAMAMevencoefficienttablesdependingontheanalogueindex(x4)andtheTCindex(x3).
0x254 txcfg_dpd_amam_even_pointer_table_4
  [25:16] MEM_TXCFG_DPD_AMAM_EVEN_PTR_TBL_TC2_ANAIDX_1 rw — StoresthepointerstothefirstaddressesoftheDPDsAMAMevencoefficienttablesdependingontheanalogueindex(x4)andtheTCindex(x3).
  [9:0] MEM_TXCFG_DPD_AMAM_EVEN_PTR_TBL_TC2_ANAIDX_0 rw — StoresthepointerstothefirstaddressesoftheDPDsAMAMevencoefficienttablesdependingontheanalogueindex(x4)andtheTCindex(x3).
0x258 txcfg_dpd_amam_even_pointer_table_5
  [25:16] MEM_TXCFG_DPD_AMAM_EVEN_PTR_TBL_TC2_ANAIDX_3 rw — StoresthepointerstothefirstaddressesoftheDPDsAMAMevencoefficienttablesdependingontheanalogueindex(x4)andtheTCindex(x3).
  [9:0] MEM_TXCFG_DPD_AMAM_EVEN_PTR_TBL_TC2_ANAIDX_2 rw — StoresthepointerstothefirstaddressesoftheDPDsAMAMevencoefficienttablesdependingontheanalogueindex(x4)andtheTCindex(x3).
0x25C txcfg_dpd_amam_odd_pointer_table_0
  [25:16] MEM_TXCFG_DPD_AMAM_ODD_PTR_TBL_TC0_ANAIDX_1 rw — StoresthepointerstothefirstaddressesoftheDPDsAMAModdcoefficienttablesdependingontheanalogueindex(x4)andtheTCindex(x3).
  [9:0] MEM_TXCFG_DPD_AMAM_ODD_PTR_TBL_TC0_ANAIDX_0 rw — StoresthepointerstothefirstaddressesoftheDPDsAMAModdcoefficienttablesdependingontheanalogueindex(x4)andtheTCindex(x3).
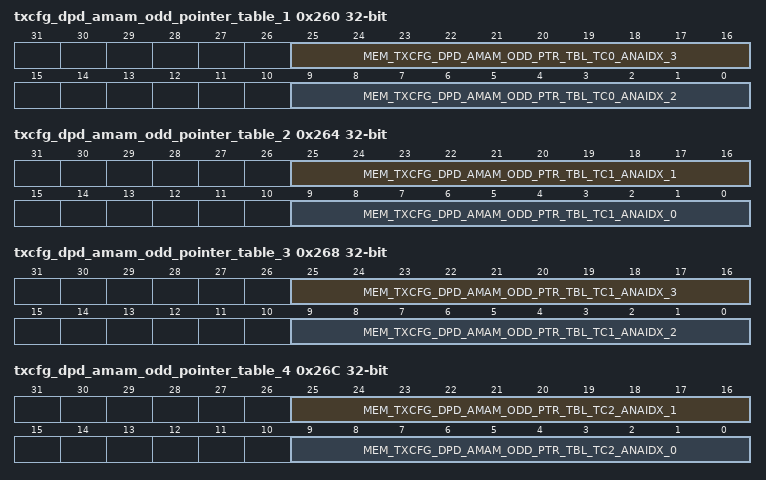
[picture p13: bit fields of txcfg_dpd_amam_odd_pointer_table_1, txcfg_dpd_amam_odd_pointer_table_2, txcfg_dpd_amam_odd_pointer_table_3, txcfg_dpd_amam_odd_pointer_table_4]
0x260 txcfg_dpd_amam_odd_pointer_table_1
  [25:16] MEM_TXCFG_DPD_AMAM_ODD_PTR_TBL_TC0_ANAIDX_3 rw — StoresthepointerstothefirstaddressesoftheDPDsAMAModdcoefficienttablesdependingontheanalogueindex(x4)andtheTCindex(x3).
  [9:0] MEM_TXCFG_DPD_AMAM_ODD_PTR_TBL_TC0_ANAIDX_2 rw — StoresthepointerstothefirstaddressesoftheDPDsAMAModdcoefficienttablesdependingontheanalogueindex(x4)andtheTCindex(x3).
0x264 txcfg_dpd_amam_odd_pointer_table_2
  [25:16] MEM_TXCFG_DPD_AMAM_ODD_PTR_TBL_TC1_ANAIDX_1 rw — StoresthepointerstothefirstaddressesoftheDPDsAMAModdcoefficienttablesdependingontheanalogueindex(x4)andtheTCindex(x3).
  [9:0] MEM_TXCFG_DPD_AMAM_ODD_PTR_TBL_TC1_ANAIDX_0 rw — StoresthepointerstothefirstaddressesoftheDPDsAMAModdcoefficienttablesdependingontheanalogueindex(x4)andtheTCindex(x3).
0x268 txcfg_dpd_amam_odd_pointer_table_3
  [25:16] MEM_TXCFG_DPD_AMAM_ODD_PTR_TBL_TC1_ANAIDX_3 rw — StoresthepointerstothefirstaddressesoftheDPDsAMAModdcoefficienttablesdependingontheanalogueindex(x4)andtheTCindex(x3).
  [9:0] MEM_TXCFG_DPD_AMAM_ODD_PTR_TBL_TC1_ANAIDX_2 rw — StoresthepointerstothefirstaddressesoftheDPDsAMAModdcoefficienttablesdependingontheanalogueindex(x4)andtheTCindex(x3).
0x26C txcfg_dpd_amam_odd_pointer_table_4
  [25:16] MEM_TXCFG_DPD_AMAM_ODD_PTR_TBL_TC2_ANAIDX_1 rw — StoresthepointerstothefirstaddressesoftheDPDsAMAModdcoefficienttablesdependingontheanalogueindex(x4)andtheTCindex(x3).
  [9:0] MEM_TXCFG_DPD_AMAM_ODD_PTR_TBL_TC2_ANAIDX_0 rw — StoresthepointerstothefirstaddressesoftheDPDsAMAModdcoefficienttablesdependingontheanalogueindex(x4)andtheTCindex(x3).
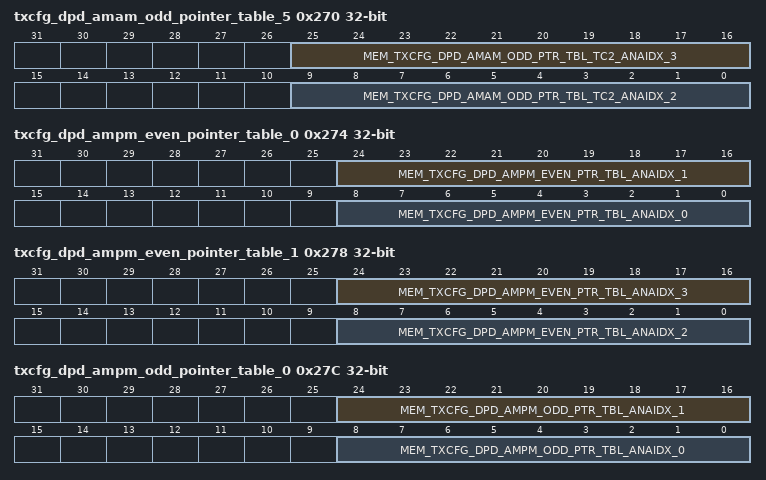
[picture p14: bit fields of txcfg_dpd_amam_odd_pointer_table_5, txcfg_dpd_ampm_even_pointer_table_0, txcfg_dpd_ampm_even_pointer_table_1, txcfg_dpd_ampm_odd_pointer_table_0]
0x270 txcfg_dpd_amam_odd_pointer_table_5
  [25:16] MEM_TXCFG_DPD_AMAM_ODD_PTR_TBL_TC2_ANAIDX_3 rw — StoresthepointerstothefirstaddressesoftheDPDsAMAModdcoefficienttablesdependingontheanalogueindex(x4)andtheTCindex(x3).
  [9:0] MEM_TXCFG_DPD_AMAM_ODD_PTR_TBL_TC2_ANAIDX_2 rw — StoresthepointerstothefirstaddressesoftheDPDsAMAModdcoefficienttablesdependingontheanalogueindex(x4)andtheTCindex(x3).
0x274 txcfg_dpd_ampm_even_pointer_table_0
  [24:16] MEM_TXCFG_DPD_AMPM_EVEN_PTR_TBL_ANAIDX_1 rw — StoresthepointerstothefirstaddressesoftheDPDsAmPmevencoefficienttablesdependingontheanalogueindex(x4).
  [8:0] MEM_TXCFG_DPD_AMPM_EVEN_PTR_TBL_ANAIDX_0 rw — StoresthepointerstothefirstaddressesoftheDPDsAmPmevencoefficienttablesdependingontheanalogueindex(x4).
0x278 txcfg_dpd_ampm_even_pointer_table_1
  [24:16] MEM_TXCFG_DPD_AMPM_EVEN_PTR_TBL_ANAIDX_3 rw — StoresthepointerstothefirstaddressesoftheDPDsAmPmevencoefficienttablesdependingontheanalogueindex(x4).
  [8:0] MEM_TXCFG_DPD_AMPM_EVEN_PTR_TBL_ANAIDX_2 rw — StoresthepointerstothefirstaddressesoftheDPDsAmPmevencoefficienttablesdependingontheanalogueindex(x4).
0x27C txcfg_dpd_ampm_odd_pointer_table_0
  [24:16] MEM_TXCFG_DPD_AMPM_ODD_PTR_TBL_ANAIDX_1 rw — StoresthepointerstothefirstaddressesoftheDPDsAmPmoddcoefficienttablesdependingontheanalogueindex(x4).
  [8:0] MEM_TXCFG_DPD_AMPM_ODD_PTR_TBL_ANAIDX_0 rw — StoresthepointerstothefirstaddressesoftheDPDsAmPmoddcoefficienttablesdependingontheanalogueindex(x4).
0x280 txcfg_dpd_ampm_odd_pointer_table_1
  [24:16] MEM_TXCFG_DPD_AMPM_ODD_PTR_TBL_ANAIDX_3 rw — StoresthepointerstothefirstaddressesoftheDPDsAmPmoddcoefficienttablesdependingontheanalogueindex(x4).
  [8:0] MEM_TXCFG_DPD_AMPM_ODD_PTR_TBL_ANAIDX_2 rw — StoresthepointerstothefirstaddressesoftheDPDsAmPmoddcoefficienttablesdependingontheanalogueindex(x4).
0x284 txcfg_non_tb_set reset 0x32100000 (reset mask 0xFFFF0000)
  [4n+3:4n] MEM_TXCFG_SHP_NON_TB_SET_{n} rw (n=0..3) — StoresthepointerstotheaddressesoftheNON_TBshapingsets.Thisincludes:
0x288 txcfg_non_tb_mirror
  [n] MEM_TXCFG_SHP_NON_TB_SET_MIR_{n} rw (n=0..3) — StoresthepointerstotheaddressesoftheNON_TBshapingsets.Thisincludes:
0x28C txcfg_shaping_set_hl reset 0xFFFF0000 (reset mask 0xFFFF0000)
  [n] MEM_TXCFG_SHP_HL_{n} rw (n=0..15) — TellswhethertheRGmeansHighorLowratestobeusedatTXCFG_SHAPING_TB.
0x290 txcfg_tb_set_0 rw reset not defined
  [4n+3:4n] MEM_TXCFG_SHP_TB_SET_HI_{n} (n=0..7) — StoresthepointerstotheaddressesoftheTBshapingsetswithrespecttoHighorLowrates.
0x294 txcfg_tb_set_1 rw reset not defined
  [4n-29:4n-32] MEM_TXCFG_SHP_TB_SET_HI_{n} (n=8..15) — StoresthepointerstotheaddressesoftheTBshapingsetswithrespecttoHighorLowrates.
0x298 txcfg_tb_set_2 rw reset not defined
  [4n+3:4n] MEM_TXCFG_SHP_TB_SET_LO_{n} (n=0..7) — StoresthepointerstotheaddressesoftheTBshapingsetswithrespecttoHighorLowrates.
0x29C txcfg_tb_set_3 rw reset not defined
  [4n-29:4n-32] MEM_TXCFG_SHP_TB_SET_LO_{n} (n=8..15) — StoresthepointerstotheaddressesoftheTBshapingsetswithrespecttoHighorLowrates.
0x2A0 txcfg_tb_mirror rw
  [n+16] MEM_TXCFG_SHP_TB_SET_MIR_LO_{n} (n=0..15) — StoresthepointerstotheaddressesoftheTBshapingsetswithrespecttoHighorLowrates.
  [n] MEM_TXCFG_SHP_TB_SET_MIR_HI_{n} (n=0..15) — StoresthepointerstotheaddressesoftheTBshapingsetswithrespecttoHighorLowrates.
0x2A4 txcfg_shaping_set_to_pointer_table_0 rw reset not defined
  [8n+7:8n] MEM_TXCFG_SHP_SET_TO_PTR_TBL_{n} (n=0..3) — StoresthepointerstothefirstaddressesoftheTxShapingcoefficienttablesdependingonthesetnumber(x16).
0x2A8 txcfg_shaping_set_to_pointer_table_1 rw reset not defined
  [8n-25:8n-32] MEM_TXCFG_SHP_SET_TO_PTR_TBL_{n} (n=4..7) — StoresthepointerstothefirstaddressesoftheTxShapingcoefficienttablesdependingonthesetnumber(x16).
0x2AC txcfg_shaping_set_to_pointer_table_2 rw reset not defined
  [8n-57:8n-64] MEM_TXCFG_SHP_SET_TO_PTR_TBL_{n} (n=8..11) — StoresthepointerstothefirstaddressesoftheTxShapingcoefficienttablesdependingonthesetnumber(x16).
0x2B0 txcfg_shaping_set_to_pointer_table_3 rw reset not defined
  [8n-89:8n-96] MEM_TXCFG_SHP_SET_TO_PTR_TBL_{n} (n=12..15) — StoresthepointerstothefirstaddressesoftheTxShapingcoefficienttablesdependingonthesetnumber(x16).
0x2B4 txcfg_window_pointer reset 0x840000 (reset mask 0xFFFFF000)
  [11:8] MEM_TXCFG_WIN_PTR_HE rw — StoresthepointerstothefirstaddressesoftheTxWindowingcoefficienttablesdependingontheformat(Legacy/HT/HEx3).3setsareavailable.
  [7:4] MEM_TXCFG_WIN_PTR_HT rw — StoresthepointerstothefirstaddressesoftheTxWindowingcoefficienttablesdependingontheformat(Legacy/HT/HEx3).3setsareavailable.
  [3:0] MEM_TXCFG_WIN_PTR_LEGACY rw — StoresthepointerstothefirstaddressesoftheTxWindowingcoefficienttablesdependingontheformat(Legacy/HT/HEx3).3setsareavailable.
0x2B8 txcfg_parr_set_lbo rw reset not defined
  [2n+1:2n] MEM_TXCFG_PARR_SET_TBL_LBO_RG_{n} (n=0..15) — StoresthePARRsetnumberforlowBOmode(+TB)setpointersperRG(x16).
0x2BC txcfg_parr_set_hbo rw reset not defined
  [2n+1:2n] MEM_TXCFG_PARR_SET_TBL_HBO_RG_{n} (n=0..15) — StoresthePARRsetnumberforhighBOsetpointersperRG(x16).
0x2C0 txcfg_parr_set_to_pointer_table reset not defined
  [8n+6:8n] MEM_TXCFG_PARR_SET_TO_PTR_TBL_{n} rw (n=0..3) — StoresthepointerstothefirstaddressesofthePARRcoefficienttablesdependingonthesetnumber(x4).
0x2C4 txcfg_dpd_amam_adder_reference
  [23:0] MEM_TXCFG_DPD_AMAM_ADDER_REF rw — DescribestheaddersreferencefortheDPDAmAmsourcepointers.
0x2C8 txcfg_dpd_ampm_adder_reference
  [23:0] MEM_TXCFG_DPD_AMPM_ADDER_REF rw — DescribestheaddersreferencefortheDPDAmPmsourcepointers.
0x2CC txcfg_shaping_adder_reference
  [23:0] MEM_TXCFG_SHP_ADDER_REF rw — DescribestheaddersreferencefortheShapingsourcepointers.
0x2D0 txcfg_window_adder_reference
  [23:0] MEM_TXCFG_WIN_ADDER_REF rw — DescribestheaddersreferencefortheWindowingsourcepointers
0x2D4 txcfg_parr_adder_reference
  [23:0] MEM_TXCFG_PARR_ADDER_REF rw — DescribestheaddersreferenceforthePARRsourcepointers
0x2D8 txcfg_dpd_amam_odd_dest
  [23:0] MEM_TXCFG_DPD_AMAM_ODD_DEST rw — HoldsthedestinationpointeroftheDPDsAmAmOddcoefficients.SeeAS-25formoredetails.
0x2DC txcfg_dpd_amam_even_dest
  [23:0] MEM_TXCFG_DPD_AMAM_EVEN_DEST rw — HoldsthedestinationpointeroftheDPDsAmAmEvencoefficients.SeeAS-25formoredetails.
0x2E0 txcfg_dpd_ampm_odd_dest
  [23:0] MEM_TXCFG_DPD_AMPM_ODD_DEST rw — HoldsthedestinationpointeroftheDPDsAmPmOddcoefficients.SeeAS-25formoredetails.
0x2E4 txcfg_dpd_ampm_even_dest
  [23:0] MEM_TXCFG_DPD_AMPM_EVEN_DEST rw — HoldsthedestinationpointeroftheDPDsAmPmEvencoefficients.SeeAS-25formoredetails.
0x2E8 txcfg_shaping_dest
  [23:0] MEM_TXCFG_SHP_DEST rw — HoldsthedestinationpointeroftheShapingcoefficients.SeeAS-25formoredetails.
0x2EC txcfg_window_dest
  [23:0] MEM_TXCFG_WIN_DEST rw — HoldsthedestinationpointeroftheWindowingcoefficients.SeeAS-25formoredetails.
0x2F0 txcfg_parr_dest
  [23:0] MEM_TXCFG_PARR_DEST rw — HoldsthedestinationpointerofthePARRcoefficientsandconfigurations.SeeAS-25formoredetails.
0x2F4 txcfg_dpd_amam_size_0 rw reset not defined
  [4n+19:4n+16] MEM_TXCFG_DPD_AMAM_SIZE_TC1_ANAIDX_{n} (n=0..3) — SetstheDPDsAmAmtablesizedependingontheanalogueindex(x4)andtheTCindex(x3).
  [4n+3:4n] MEM_TXCFG_DPD_AMAM_SIZE_TC0_ANAIDX_{n} (n=0..3) — SetstheDPDsAmAmtablesizedependingontheanalogueindex(x4)andtheTCindex(x3).
0x2F8 txcfg_dpd_amam_size_1 reset 0x44440000 (reset mask 0xFFFF0000)
  [4n+3:4n] MEM_TXCFG_DPD_AMAM_SIZE_TC2_ANAIDX_{n} rw (n=0..3) — SetstheDPDsAmAmtablesizedependingontheanalogueindex(x4)andtheTCindex(x3).
0x2FC txcfg_dpd_ampm_size reset 0x44440000 (reset mask 0xFFFF0000)
  [4n+3:4n] MEM_TXCFG_DPD_AMPM_SIZE_ANAIDX_{n} rw (n=0..3) — SetstheDPDsAmPmtablesizedependingontheanalogueindex(x4).
0x300 txcfg_window_size reset 0x44
  [3:0] MEM_TXCFG_WIN_SIZE rw — Setsthecoefficientcountcopiedtothewindowingmodule.SeeAS-22formoredetails.
0x304 txcfg_parr_size reset 0x252
  [4:0] MEM_TXCFG_PARR_SIZE rw — SetsthecoefficientcountcopiedtothePARRmodule.SeeAS-23formoredetails.
0x308 txcfg_shaping_size reset 0x2B5
  [4:0] MEM_TXCFG_SHP_SIZE rw — SetsthecoefficientcountcopiedtotheShapingmodule.SeeAS-24formoredetails.
0x30C txcfg_dpd_amam_even_address_chosen ro
  [23:0] TXCFG_DPD_AMAM_EVEN_ADDR_CHOSEN — StatusROregisterthatindicatesthechosenDPDevenAmAmtablesAddress.Thisvalueisaftertheadder.
0x310 txcfg_dpd_amam_odd_address_chosen ro
  [23:0] TXCFG_DPD_AMAM_ODD_ADDR_CHOSEN — StatusROregisterthatindicatesthechosenDPDoddAmAmtablespointer.Thisvalueisaftertheadder.
0x314 txcfg_dpd_ampm_even_address_chosen ro
  [23:0] TXCFG_DPD_AMPM_EVEN_ADDR_CHOSEN — StatusROregisterthatindicatesthechosenDPDevenAmPmtablespointer.Thisvalueisaftertheadder.
0x318 txcfg_dpd_ampm_odd_address_chosen ro
  [23:0] TXCFG_DPD_AMPM_ODD_ADDR_CHOSEN — StatusROregisterthatindicatesthechosenDPDoddAmPmtablespointer.Thisvalueisaftertheadder.
0x31C txcfg_window_address_chosen ro
  [23:0] TXCFG_WIN_ADDR_CHOSEN — StatusROregisterthatindicatesthechosenTxWindowingtablespointer.Thisvalueisaftertheadder.
0x320 txcfg_window_pointer_chosen ro
  [3:0] TXCFG_WIN_PTR_CHOSEN — StatusROregisterthatindicatesthechosenwindowingcoefficientset.
0x324 txcfg_parr_address_chosen ro
  [23:0] TXCFG_PARR_ADDR_CHOSEN — StatusROregisterthatindicatesthechosenPARRcoefficienttablespointer.Thisvalueisaftertheadder.
0x328 txcfg_parr_set_chosen ro
  [1:0] TXCFG_PARR_SET_CHOSEN — StatusROregisterthatindicatesthechosenPARRcoefficientset.
0x32C txcfg_parr_pointer_chosen ro
  [6:0] TXCFG_PARR_PTR_CHOSEN — StatusROregisterthatindicatesthechosenPARRcoefficientpointercorrespondingtothechosenPARRset.
0x330 txcfg_shaping_address_chosen ro
  [23:0] TXCFG_SHP_ADDR_CHOSEN — StatusROregisterthatindicatesthechosenTxShapingtablespointer.Thisvalueisaftertheadder.
0x334 txcfg_shaping_set_chosen ro
  [3:0] TXCFG_SHP_SET_CHOSEN — StatusROregisterthatindicatesthechosenTxShapingcoefficientset.
0x338 txcfg_shaping_pointer_chosen ro
  [7:0] TXCFG_SHP_PTR_CHOSEN — StatusROregisterthatindicatesthechosenTxShapingcoefficientpointer.
0x33C txcfg_dpd_amam_size_chosen ro
  [3:0] TXCFG_DPD_AMAM_SIZE_CHOSEN — StatusROregisterthatindicatesthechosenDPDAmAmtablesize.
0x340 txcfg_dpd_ampm_size_chosen ro
  [3:0] TXCFG_DPD_AMPM_SIZE_CHOSEN — StatusROregisterthatindicatesthechosenDPDAmPmtablesize.
0x344 txcfg_force_dpd_amam_even_pointer
  [0] MEM_TXCFG_FORCE_DPD_AMAM_EVEN_PTR rw — ForcestheDMAtousetheDPDAmAmevencoefficientpointerfromadesignatedregister:TXCFG_DPD_AMAM_EVEN_POINTER_OVD.
0x348 txcfg_dpd_amam_even_pointer_ovd
  [9:0] MEM_TXCFG_DPD_AMAM_EVEN_PTR_OVD rw — OverridestheDPDAmAmevencoefficientpointertobeusedbytheDMA.
0x34C txcfg_force_dpd_amam_odd_pointer
  [0] MEM_TXCFG_FORCE_DPD_AMAM_ODD_PTR rw — ForcestheDMAtousetheDPDAmAmoddcoefficientpointerfromadesignatedregister:TXCFG_DPD_AMAM_ODD_POINTER_OVD.
0x350 txcfg_dpd_amam_odd_pointer_ovd
  [9:0] MEM_TXCFG_DPD_AMAM_ODD_PTR_OVD rw — OverridestheDPDAmAmoddcoefficientpointertobeusedbytheDMA.
0x354 txcfg_force_dpd_ampm_even_pointer
  [0] MEM_TXCFG_FORCE_DPD_AMPM_EVEN_PTR rw — ForcestheDMAtousetheDPDAmPmevencoefficientpointerfromadesignatedregister:TXCFG_DPD_AMPM_EVEN_POINTER_OVD.
0x358 txcfg_dpd_ampm_even_pointer_ovd
  [8:0] MEM_TXCFG_DPD_AMPM_EVEN_PTR_OVD rw — OverridestheDPDAmPmevencoefficientpointertobeusedbytheDMA.
0x35C txcfg_force_dpd_ampm_odd_pointer
  [0] MEM_TXCFG_FORCE_DPD_AMPM_ODD_PTR rw — ForcestheDMAtousetheDPDAmPmoddcoefficientpointerfromadesignatedregister:TXCFG_DPD_AMPM_ODD_POINTER_OVD.
0x360 txcfg_dpd_ampm_odd_pointer_ovd
  [8:0] MEM_TXCFG_DPD_AMPM_ODD_PTR_OVD rw — OverridestheDPDAmPmoddcoefficientpointertobeusedbytheDMA.
0x364 txcfg_force_shaping_set
  [0] MEM_TXCFG_FORCE_SHP_SET rw — ForcestheDMAtousetheShapingcoefficientsetfromadesignatedregister:TXCFG_SHAPING_SET_OVD.
0x368 txcfg_shaping_set_ovd
  [3:0] MEM_TXCFG_SHP_SET_OVD rw — OverridestheShapingsettobeusedbytheDMA.
0x36C txcfg_force_window_pointer
  [0] MEM_TXCFG_FORCE_WIN_PTR rw — ForcestheDMAtousetheWindowingpointerfromadesignatedregister:TXCFG_WINDOW_POINTER_OVD
0x370 txcfg_window_pointer_ovd
  [3:0] MEM_TXCFG_WIN_PTR_OVD rw — OverridestheWindowingsettobeusedbytheDMA.
0x374 txcfg_force_parr_set
  [0] MEM_TXCFG_FORCE_PARR_SET rw — ForcestheDMAtousethePARRsetfromadesignatedregister:TXCFG_SHAPING_SET_OVD.
0x378 txcfg_parr_set_ovd
  [1:0] MEM_TXCFG_PARR_SET_OVD rw — OverridesthePARRsettobeusedbytheDMA.
0x37C txcfg_force_dpd_amam_size
  [0] MEM_TXCFG_FORCE_DPD_AMAM_SIZE rw — ForcestheDMAtousetheDPDAmAmsizefromadesignatedregister:TXCFG_DPD_AMAM_SIZE_OVD.
0x380 txcfg_dpd_amam_size_ovd
  [3:0] MEM_TXCFG_DPD_AMAM_SIZE_OVD rw — OverridestheDPDAmAmsizetobeusedbytheDMA.
0x384 txcfg_force_dpd_ampm_size
  [0] MEM_TXCFG_FORCE_DPD_AMPM_SIZE rw — ForcestheDMAtousetheDPDAmPmsizefromadesignatedregister:TXCFG_DPD_AMPM_SIZE_OVD.
0x388 txcfg_dpd_ampm_size_ovd
  [3:0] MEM_TXCFG_DPD_AMPM_SIZE_OVD rw — OverridestheDPDAmPmsizetobeusedbytheDMA.
0x38C txcfg_force_lin_gain
  [0] MEM_TXCFG_FORCE_LIN_GAIN rw — ForcestheTxConfigmoduletooutputspecificlineargainvaluestowardstheDPDandRFNL.
0x390 txcfg_lin_gain_ovd
  [17:16] MEM_TXCFG_COARSE_GAIN_OVD rw — Overridethecoarsegainoutputwithapredeterminedvalue
  [8:0] MEM_TXCFG_FINE_GAIN_OVD rw — Overridethefinegainoutputwithapredeterminedvalue
0x394 txcfg_post_lin_gain_ovd
  [17:16] MEM_TXCFG_POST_COARSE_GAIN_OVD rw — Overridethepostcoarsegainoutputwithapredeterminedvalue
  [8:0] MEM_TXCFG_POST_FINE_GAIN_OVD rw — Overridethepostfinegainoutputwithapredeterminedvalue
0x398 txcfg_dma_en reset 0x3
  [0] MEM_TXCFG_DMA_EN rw — EnablestheDMAcopyingsession.
0x39C txcfg_dma_order rw reset 0x1234567
  [31:0] MEM_TXCFG_DMA_ORDER — SetstheDMApointerorder:;Wehave7differentpointerstosetorderto:;0.DPD_AmAm_Even.;1.DPD_AmAm_Odd.;2.Windowing.;3.Shaping.;4.PARR.;5.DPD_AmPm_Even.;6.DPD_AmPm_Odd.;Eachtablewillhaveauniquenumberfrom0to7.Thesenumberswillbesetin4bitsections whentheMSBcanpausetheDMAswork(seeAS-26andreasoning#5formoredetails).Thefirstnumberintheregister(atthe4MSBs)isthefirstinorder.
0x3A0 txcfg_dma_stop_job reset 0x36
  [2:0] MEM_TXCFG_DMA_STOP_JOB rw — HoldsthelastjobnumbertheDMAshouldcopy.
0x3A4 txcfg_dma_cmd
  [1] TXCFG_DMA_RESUME_WRCL wo — TellstheDMAtocontinueitsoperationfromwhereitwaspaused.
  [0] TXCFG_DMA_PAUSE_WRCL wo — TellstheDMAtopauseitsoperationwhenthecurrentjobisfinished.
0x3A8 txcfg_dma_ctrl
  [0] MEM_TXCFG_DMA_CTRL_IS_FW rw — ChoosesfromtheFWandHWregisters
0x3AC txcfg_dma_fw_trig
  [0] TXCFG_DMA_FW_TRIG_WRCL wo — TellstheDMAtostartitsoperationfromthestart.
0x3B0 txcfg_dma_fw_source
  [23:0] MEM_TXCFG_DMA_FW_SOURCE rw — HoldstheFWsourceaddress
0x3B4 txcfg_dma_fw_dest
  [23:0] MEM_TXCFG_DMA_FW_DEST rw — HoldstheFWdestinationaddress.
0x3B8 txcfg_dma_fw_size
  [7:0] MEM_TXCFG_DMA_FW_SIZE rw — HoldstheFWsizevalue.
0x3BC txcfg_dma_status ro
  [2] TXCFG_DMA_DONE — StatusregisterthattellsusthattheDMAisdone.
  [1] TXCFG_DMA_PAUSED — StatusregisterthattellsusthattheDMAispaused.
  [0] TXCFG_DMA_BUSY — StatusregisterthattellsusthattheDMAisbusy.
0x3C0 tx_cfg_tc_cfg_0 rw reset not defined
  [8n+7:8n] MEM_TXCFG_TCIDX_0_PARR_DIS_{n} (n=0..3)
0x3C4 tx_cfg_tc_cfg_1 rw reset not defined
  [8n-25:8n-32] MEM_TXCFG_TCIDX_0_PARR_DIS_{n} (n=4..7)
0x3C8 tx_cfg_tc_cfg_2 rw reset not defined
  [8n+7:8n] MEM_TXCFG_TCIDX_1_PARR_DIS_{n} (n=0..3)
0x3CC tx_cfg_tc_cfg_3 rw reset not defined
  [8n-25:8n-32] MEM_TXCFG_TCIDX_1_PARR_DIS_{n} (n=4..7)
0x3D0 tx_cfg_tc_cfg_4 rw reset not defined
  [8n+7:8n] MEM_TXCFG_TCIDX_2_PARR_DIS_{n} (n=0..3)
0x3D4 tx_cfg_tc_cfg_5 rw reset not defined
  [8n-25:8n-32] MEM_TXCFG_TCIDX_2_PARR_DIS_{n} (n=4..7)
0x3D8 tx_cfg_tc_cfg_6 rw reset not defined
  [8n+7:8n] MEM_TXCFG_TCIDX_0_PARR_EN_{n} (n=0..3)
0x3DC tx_cfg_tc_cfg_7 rw reset not defined
  [8n-25:8n-32] MEM_TXCFG_TCIDX_0_PARR_EN_{n} (n=4..7)
0x3E0 tx_cfg_tc_cfg_8 rw reset not defined
  [8n+7:8n] MEM_TXCFG_TCIDX_1_PARR_EN_{n} (n=0..3)
0x3E4 tx_cfg_tc_cfg_9 rw reset not defined
  [8n-25:8n-32] MEM_TXCFG_TCIDX_1_PARR_EN_{n} (n=4..7)
0x3E8 tx_cfg_tc_cfg_10 rw reset not defined
  [8n+7:8n] MEM_TXCFG_TCIDX_2_PARR_EN_{n} (n=0..3)
0x3EC tx_cfg_tc_cfg_11 rw reset not defined
  [8n-25:8n-32] MEM_TXCFG_TCIDX_2_PARR_EN_{n} (n=4..7)
